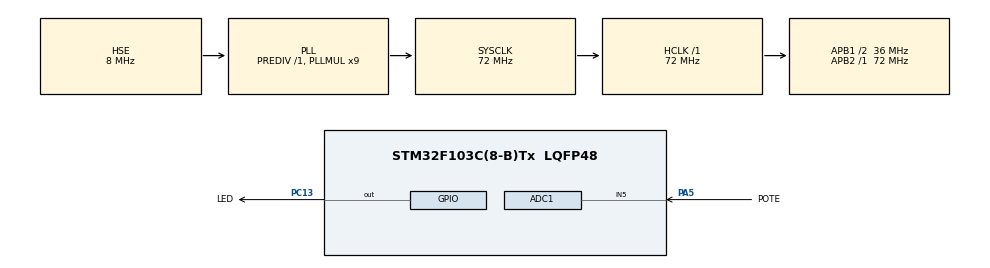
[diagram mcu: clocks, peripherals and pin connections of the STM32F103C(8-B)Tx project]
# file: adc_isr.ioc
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Mcu.Family=STM32F1
RCC.PLLSourceVirtual=RCC_PLLSOURCE_HSE
NVIC.ADC1_2_IRQn=true\:5\:0\:true\:false\:true\:true\:true
PD1-OSC_OUT.Mode=HSE-External-Oscillator
PC13-TAMPER-RTC.Signal=GPIO_Output
NVIC.TIM1_UP_IRQn=true\:0\:0\:false\:false\:true\:false\:true
PD0-OSC_IN.Signal=RCC_OSC_IN
RCC.APB1CLKDivider=RCC_HCLK_DIV2
RCC.SYSCLKSource=RCC_SYSCLKSOURCE_PLLCLK
ProjectManager.StackSize=0x400
PD1-OSC_OUT.Signal=RCC_OSC_OUT
RCC.ADCPresc=RCC_ADCPCLK2_DIV6
PA13.Signal=SYS_JTMS-SWDIO
ProjectManager.TargetToolchain=STM32CubeIDE
RCC.HCLKFreq_Value=72000000
RCC.APB2TimFreq_Value=72000000
ADC1.Channel-1\#ChannelRegularConversion=ADC_CHANNEL_5
RCC.USBFreq_Value=72000000
RCC.AHBFreq_Value=72000000
PD0-OSC_IN.Mode=HSE-External-Oscillator
PA5.Signal=ADCx_IN5
board=custom
RCC.PLLMUL=RCC_PLL_MUL9
PC13-TAMPER-RTC.GPIO_Label=LED
RCC.APB2Freq_Value=72000000
PA14.Mode=Serial_Wire
VP_SYS_VS_tim1.Mode=TIM1
PA13.Mode=Serial_Wire
Mcu.Name=STM32F103C(8-B)Tx
ADC1.SamplingTime-1\#ChannelRegularConversion=ADC_SAMPLETIME_1CYCLE_5
RCC.SYSCLKFreq_VALUE=72000000
Mcu.Package=LQFP48
ADC1.master=1
NVIC.TimeBase=TIM1_UP_IRQn
PA5.GPIO_Label=POTE
ADC1.Rank-1\#ChannelRegularConversion=1
NVIC.TimeBaseIP=TIM1
PA14.Signal=SYS_JTCK-SWCLK
ProjectManager.HeapSize=0x200
SH.ADCx_IN5.0=ADC1_IN5,IN5
NVIC.PriorityGroup=NVIC_PRIORITYGROUP_4
ADC1.NbrOfConversionFlag=1
RCC.APB1TimFreq_Value=72000000
RCC.APB1Freq_Value=36000000

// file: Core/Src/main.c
/* USER CODE BEGIN Header */
/*
 * The following code consists of 2 tasks:
 *  - The first one periodically starts a new ADC conversion. The result will be handled via ISR, and the result will be written in a queue.
 *  - The second task reads the value from the queue and then turns on/off the led according to a threshold value
 */
/* USER CODE END Header */
#include "main.h"

/* USER CODE BEGIN Includes */
#include "FreeRTOS.h"
#include "task.h"
#include "queue.h"
/* USER CODE END Includes */

ADC_HandleTypeDef hadc1;

void SystemClock_Config(void);
static void MX_GPIO_Init(void);
static void MX_ADC1_Init(void);

/* USER CODE BEGIN 0 */

QueueHandle_t adc_queue;

#define THRESHOLD_VALUE 2048

static void Adc(void *pvParameters){

	while (1){

		// Starts conversion
		HAL_ADC_Start_IT(&hadc1);

		// This delay marks the conversion rate
		vTaskDelay(100/portTICK_PERIOD_MS);
	}
}

static void Led(void *pvParameters){

	uint16_t received_value;

	while (1){

		// Reads the value from the queue
		xQueueReceive(adc_queue,&received_value,portMAX_DELAY);

		if ( received_value > THRESHOLD_VALUE ) {

			// If the value coming from the queue is greater than the threshold, turn on the led
			HAL_GPIO_WritePin(LED_GPIO_Port, LED_Pin, GPIO_PIN_RESET);

		}
		else {

			// Else turn it off
			HAL_GPIO_WritePin(LED_GPIO_Port, LED_Pin, GPIO_PIN_SET);

		}

	}
}

void HAL_ADC_ConvCpltCallback(ADC_HandleTypeDef* hadc)
{
	static portBASE_TYPE xHigherPriorityTaskWoken = pdFALSE;
	static uint16_t adc_value = 0;

	// Obtains the conversion result
	adc_value = HAL_ADC_GetValue(hadc);

	// Sends the value to the queue
	xQueueOverwriteFromISR(adc_queue, &adc_value, &xHigherPriorityTaskWoken);

	portEND_SWITCHING_ISR(xHigherPriorityTaskWoken);

	//dos botones: max: 1981
	//boton up: 2750
	//boton min: 2574
}

/* USER CODE END 0 */

int main(void)
{

  /* MCU Configuration--------------------------------------------------------*/

  /* Reset of all peripherals, Initializes the Flash interface and the Systick. */
  HAL_Init();

  /* Configure the system clock */
  SystemClock_Config();

  /* Initialize all configured peripherals */
  MX_GPIO_Init();
  MX_ADC1_Init();
  /* USER CODE BEGIN 2 */

  adc_queue = xQueueCreate(1,sizeof(uint16_t));

  xTaskCreate(Adc, "ADC task", configMINIMAL_STACK_SIZE, NULL, 1, NULL);
  xTaskCreate(Led, "Led task", configMINIMAL_STACK_SIZE, NULL, 1, NULL);

  vTaskStartScheduler();

  /* USER CODE END 2 */

  /* Infinite loop */

}

void SystemClock_Config(void)
{
  RCC_OscInitTypeDef RCC_OscInitStruct = {0};
  RCC_ClkInitTypeDef RCC_ClkInitStruct = {0};
  RCC_PeriphCLKInitTypeDef PeriphClkInit = {0};

  /** Initializes the RCC Oscillators according to the specified parameters
  * in the RCC_OscInitTypeDef structure.
  */
  RCC_OscInitStruct.OscillatorType = RCC_OSCILLATORTYPE_HSE;
  RCC_OscInitStruct.HSEState = RCC_HSE_ON;
  RCC_OscInitStruct.HSEPredivValue = RCC_HSE_PREDIV_DIV1;
  RCC_OscInitStruct.HSIState = RCC_HSI_ON;
  RCC_OscInitStruct.PLL.PLLState = RCC_PLL_ON;
  RCC_OscInitStruct.PLL.PLLSource = RCC_PLLSOURCE_HSE;
  RCC_OscInitStruct.PLL.PLLMUL = RCC_PLL_MUL9;
  if (HAL_RCC_OscConfig(&RCC_OscInitStruct) != HAL_OK)
  {
    Error_Handler();
  }
  /** Initializes the CPU, AHB and APB buses clocks
  */
  RCC_ClkInitStruct.ClockType = RCC_CLOCKTYPE_HCLK|RCC_CLOCKTYPE_SYSCLK
                              |RCC_CLOCKTYPE_PCLK1|RCC_CLOCKTYPE_PCLK2;
  RCC_ClkInitStruct.SYSCLKSource = RCC_SYSCLKSOURCE_PLLCLK;
  RCC_ClkInitStruct.AHBCLKDivider = RCC_SYSCLK_DIV1;
  RCC_ClkInitStruct.APB1CLKDivider = RCC_HCLK_DIV2;
  RCC_ClkInitStruct.APB2CLKDivider = RCC_HCLK_DIV1;

  if (HAL_RCC_ClockConfig(&RCC_ClkInitStruct, FLASH_LATENCY_2) != HAL_OK)
  {
    Error_Handler();
  }
  PeriphClkInit.PeriphClockSelection = RCC_PERIPHCLK_ADC;
  PeriphClkInit.AdcClockSelection = RCC_ADCPCLK2_DIV6;
  if (HAL_RCCEx_PeriphCLKConfig(&PeriphClkInit) != HAL_OK)
  {
    Error_Handler();
  }
}

static void MX_ADC1_Init(void)
{

  ADC_ChannelConfTypeDef sConfig = {0};

  /** Common config
  */
  hadc1.Instance = ADC1;
  hadc1.Init.ScanConvMode = ADC_SCAN_DISABLE;
  hadc1.Init.ContinuousConvMode = DISABLE;
  hadc1.Init.DiscontinuousConvMode = DISABLE;
  hadc1.Init.ExternalTrigConv = ADC_SOFTWARE_START;
  hadc1.Init.DataAlign = ADC_DATAALIGN_RIGHT;
  hadc1.Init.NbrOfConversion = 1;
  if (HAL_ADC_Init(&hadc1) != HAL_OK)
  {
    Error_Handler();
  }
  /** Configure Regular Channel
  */
  sConfig.Channel = ADC_CHANNEL_5;
  sConfig.Rank = ADC_REGULAR_RANK_1;
  sConfig.SamplingTime = ADC_SAMPLETIME_1CYCLE_5;
  if (HAL_ADC_ConfigChannel(&hadc1, &sConfig) != HAL_OK)
  {
    Error_Handler();
  }

}

static void MX_GPIO_Init(void)
{
  GPIO_InitTypeDef GPIO_InitStruct = {0};

  /* GPIO Ports Clock Enable */
  __HAL_RCC_GPIOC_CLK_ENABLE();
  __HAL_RCC_GPIOD_CLK_ENABLE();
  __HAL_RCC_GPIOA_CLK_ENABLE();

  /*Configure GPIO pin Output Level */
  HAL_GPIO_WritePin(LED_GPIO_Port, LED_Pin, GPIO_PIN_RESET);

  /*Configure GPIO pin : LED_Pin */
  GPIO_InitStruct.Pin = LED_Pin;
  GPIO_InitStruct.Mode = GPIO_MODE_OUTPUT_PP;
  GPIO_InitStruct.Pull = GPIO_NOPULL;
  GPIO_InitStruct.Speed = GPIO_SPEED_FREQ_LOW;
  HAL_GPIO_Init(LED_GPIO_Port, &GPIO_InitStruct);

}

 /**
  * @brief  Period elapsed callback in non blocking mode
  * @note   This function is called  when TIM1 interrupt took place, inside
  * HAL_TIM_IRQHandler(). It makes a direct call to HAL_IncTick() to increment
  * a global variable "uwTick" used as application time base.
  * @param  htim : TIM handle
  * @retval None
  */
void HAL_TIM_PeriodElapsedCallback(TIM_HandleTypeDef *htim)
{
  if (htim->Instance == TIM1) {
    HAL_IncTick();
  }
}

void Error_Handler(void)
{
  __disable_irq();
  while (1)
  {
  }
}

/************************ (C) COPYRIGHT STMicroelectronics *****END OF FILE****/
